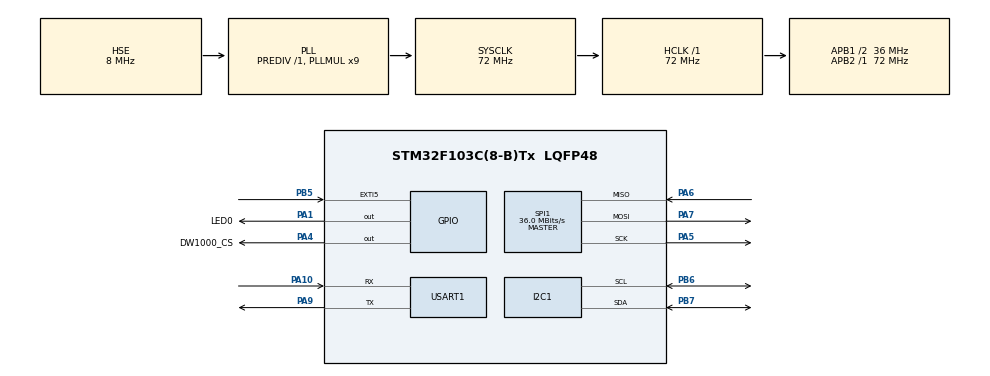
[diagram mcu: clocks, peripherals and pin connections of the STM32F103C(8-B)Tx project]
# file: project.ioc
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Dma.Request0=USART1_RX
Dma.Request1=USART1_TX
Dma.USART1_RX.0.Direction=DMA_PERIPH_TO_MEMORY
Dma.USART1_RX.0.Instance=DMA1_Channel5
Dma.USART1_RX.0.MemDataAlignment=DMA_MDATAALIGN_BYTE
Dma.USART1_RX.0.MemInc=DMA_MINC_ENABLE
Dma.USART1_RX.0.Mode=DMA_CIRCULAR
Dma.USART1_RX.0.PeriphDataAlignment=DMA_PDATAALIGN_BYTE
Dma.USART1_RX.0.PeriphInc=DMA_PINC_DISABLE
Dma.USART1_RX.0.Priority=DMA_PRIORITY_HIGH
Dma.USART1_TX.1.Direction=DMA_MEMORY_TO_PERIPH
Dma.USART1_TX.1.Instance=DMA1_Channel4
Dma.USART1_TX.1.MemDataAlignment=DMA_MDATAALIGN_BYTE
Dma.USART1_TX.1.MemInc=DMA_MINC_ENABLE
Dma.USART1_TX.1.Mode=DMA_NORMAL
Dma.USART1_TX.1.PeriphDataAlignment=DMA_PDATAALIGN_BYTE
Dma.USART1_TX.1.PeriphInc=DMA_PINC_DISABLE
Dma.USART1_TX.1.Priority=DMA_PRIORITY_HIGH
I2C1.NoStretchMode=I2C_NOSTRETCH_DISABLE
IWDG.Prescaler=IWDG_PRESCALER_64
IWDG.Reload=625
Mcu.Family=STM32F1
Mcu.Name=STM32F103C(8-B)Tx
Mcu.Package=LQFP48
NVIC.DMA1_Channel4_IRQn=true\:10\:0\:true\:false\:true\:false\:true\:true
NVIC.DMA1_Channel5_IRQn=true\:10\:0\:true\:false\:true\:false\:true\:true
NVIC.EXTI9_5_IRQn=true\:1\:0\:true\:false\:true\:true\:true\:true
NVIC.PriorityGroup=NVIC_PRIORITYGROUP_4
NVIC.SPI1_IRQn=true\:0\:0\:true\:false\:true\:true\:true\:true
NVIC.TIM2_IRQn=true\:11\:0\:true\:false\:true\:true\:true\:true
PA1.GPIO_Label=LED0
PA1.GPIO_PuPd=GPIO_PULLUP
PA1.PinState=GPIO_PIN_SET
PA1.Signal=GPIO_Output
PA10.Mode=Asynchronous
PA10.Signal=USART1_RX
PA13.Mode=Serial_Wire
PA13.Signal=SYS_JTMS-SWDIO
PA14.Mode=Serial_Wire
PA14.Signal=SYS_JTCK-SWCLK
PA4.GPIO_Label=DW1000_CS
PA4.GPIO_PuPd=GPIO_NOPULL
PA4.GPIO_Speed=GPIO_SPEED_FREQ_HIGH
PA4.PinState=GPIO_PIN_SET
PA4.Signal=GPIO_Output
PA5.Mode=Full_Duplex_Master
PA5.Signal=SPI1_SCK
PA6.Mode=Full_Duplex_Master
PA6.Signal=SPI1_MISO
PA7.Mode=Full_Duplex_Master
PA7.Signal=SPI1_MOSI
PA9.Mode=Asynchronous
PA9.Signal=USART1_TX
PB5.GPIO_ModeDefaultEXTI=GPIO_MODE_IT_RISING
PB5.GPIO_PuPd=GPIO_PULLDOWN
PB5.Signal=GPXTI5
PB6.Mode=I2C
PB6.Signal=I2C1_SCL
PB7.Mode=I2C
PB7.Signal=I2C1_SDA
PC14-OSC32_IN.Mode=LSE-External-Oscillator
PC14-OSC32_IN.Signal=RCC_OSC32_IN
PC15-OSC32_OUT.Mode=LSE-External-Oscillator
PC15-OSC32_OUT.Signal=RCC_OSC32_OUT
PD0-OSC_IN.Mode=HSE-External-Oscillator
PD0-OSC_IN.Signal=RCC_OSC_IN
PD1-OSC_OUT.Mode=HSE-External-Oscillator
PD1-OSC_OUT.Signal=RCC_OSC_OUT
ProjectManager.HeapSize=0x200
ProjectManager.StackSize=0x400
ProjectManager.TargetToolchain=STM32CubeIDE
RCC.AHBFreq_Value=72000000
RCC.APB1CLKDivider=RCC_HCLK_DIV2
RCC.APB1Freq_Value=36000000
RCC.APB1TimFreq_Value=72000000
RCC.APB2Freq_Value=72000000
RCC.APB2TimFreq_Value=72000000
RCC.HCLKFreq_Value=72000000
RCC.PLLMUL=RCC_PLL_MUL9
RCC.PLLSourceVirtual=RCC_PLLSOURCE_HSE
RCC.SYSCLKFreq_VALUE=72000000
RCC.SYSCLKSource=RCC_SYSCLKSOURCE_PLLCLK
RCC.USBFreq_Value=72000000
SPI1.BaudRatePrescaler=SPI_BAUDRATEPRESCALER_2
SPI1.CalculateBaudRate=36.0 MBits/s
SPI1.Direction=SPI_DIRECTION_2LINES
SPI1.Mode=SPI_MODE_MASTER
SPI1.VirtualType=VM_MASTER
TIM2.AutoReloadPreload=TIM_AUTORELOAD_PRELOAD_ENABLE
TIM2.Period=999
TIM2.Prescaler=7199
USART1.VirtualMode=VM_ASYNC
VP_IWDG_VS_IWDG.Mode=IWDG_Activate
VP_TIM2_VS_ClockSourceINT.Mode=Internal
board=custom

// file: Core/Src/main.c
/* USER CODE BEGIN Header */
/**
  ******************************************************************************
  * @file           : main.c
  * @brief          : Main program body
  ******************************************************************************
  * @attention
  *
  * Copyright (c) 2025 STMicroelectronics.
  * All rights reserved.
  *
  * This software is licensed under terms that can be found in the LICENSE file
  * in the root directory of this software component.
  * If no LICENSE file comes with this software, it is provided AS-IS.
  *
  ******************************************************************************
  */
/* USER CODE END Header */

#include "main.h"
#include "dma.h"
#include "i2c.h"
#include "iwdg.h"
#include "spi.h"
#include "tim.h"
#include "usart.h"
#include "gpio.h"

/* USER CODE BEGIN Includes */
#include "OLED_I2C.h"
#include <assert.h>

volatile uint32_t time32_incr = 0; // 确保加上 volatile 修饰符
uint16_t USART1_SendBuffer(const char* buffer, uint16_t length, int flag);
// 添加 _dbg_printf 的声明

/* USER CODE END Includes */

void SystemClock_Config(void);

/* USER CODE BEGIN 0 */

void EnableFlashPrefetchBuffer(void)
{
  __HAL_FLASH_PREFETCH_BUFFER_ENABLE();
}

/* USER CODE END 0 */

int main(void)
{

  /* MCU Configuration--------------------------------------------------------*/

  /* Reset of all peripherals, Initializes the Flash interface and the Systick. */
  HAL_Init();

  /* Configure the system clock */
  SystemClock_Config();

  /* Initialize all configured peripherals */
  MX_GPIO_Init();
  MX_DMA_Init();
  MX_SPI1_Init();
  MX_USART1_UART_Init();
//  MX_IWDG_Init();
  MX_TIM2_Init();
  MX_I2C1_Init();

  /* Infinite loop */
  /* USER CODE BEGIN WHILE */
  while (1)
  {

	  ds_twr_sts_sdc_initiator();

    /* USER CODE END WHILE */

  }
}

void SystemClock_Config(void)
{
  RCC_OscInitTypeDef RCC_OscInitStruct = {0};
  RCC_ClkInitTypeDef RCC_ClkInitStruct = {0};

  /** Initializes the RCC Oscillators according to the specified parameters
  * in the RCC_OscInitTypeDef structure.
  */
  RCC_OscInitStruct.OscillatorType = RCC_OSCILLATORTYPE_LSI|RCC_OSCILLATORTYPE_HSE;
  RCC_OscInitStruct.HSEState = RCC_HSE_ON;
  RCC_OscInitStruct.HSEPredivValue = RCC_HSE_PREDIV_DIV1;
  RCC_OscInitStruct.HSIState = RCC_HSI_ON;
  RCC_OscInitStruct.LSIState = RCC_LSI_ON;
  RCC_OscInitStruct.PLL.PLLState = RCC_PLL_ON;
  RCC_OscInitStruct.PLL.PLLSource = RCC_PLLSOURCE_HSE;
  RCC_OscInitStruct.PLL.PLLMUL = RCC_PLL_MUL9;
  if (HAL_RCC_OscConfig(&RCC_OscInitStruct) != HAL_OK)
  {
    Error_Handler();
  }

  /** Initializes the CPU, AHB and APB buses clocks
  */
  RCC_ClkInitStruct.ClockType = RCC_CLOCKTYPE_HCLK|RCC_CLOCKTYPE_SYSCLK
                              |RCC_CLOCKTYPE_PCLK1|RCC_CLOCKTYPE_PCLK2;
  RCC_ClkInitStruct.SYSCLKSource = RCC_SYSCLKSOURCE_PLLCLK;
  RCC_ClkInitStruct.AHBCLKDivider = RCC_SYSCLK_DIV1;
  RCC_ClkInitStruct.APB1CLKDivider = RCC_HCLK_DIV2;
  RCC_ClkInitStruct.APB2CLKDivider = RCC_HCLK_DIV1;

  if (HAL_RCC_ClockConfig(&RCC_ClkInitStruct, FLASH_LATENCY_2) != HAL_OK)
  {
    Error_Handler();
  }
}

void Error_Handler(void)
{
  __disable_irq();
  while (1)
  {
  }
}
